AUTOSAR XML (schema 4.0)
package /Powertrain_Components
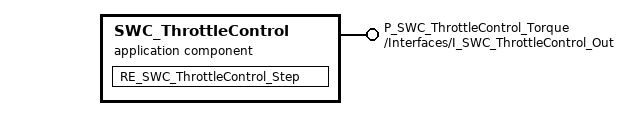
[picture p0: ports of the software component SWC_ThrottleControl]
  application sw component type SWC_ThrottleControl  # AUTOSAR Application SWC SWC_ThrottleControl for Powertrain Control
    provide port P_SWC_ThrottleControl_Torque: provided-interface=/Interfaces/I_SWC_ThrottleControl_Out
    behavior SWC_ThrottleControl_Behavior
      runnable RE_SWC_ThrottleControl_Step: symbol=SWC_ThrottleControl_Step
  sender receiver interface I_SWC_ThrottleControl_Out
    data DE_SWC_ThrottleControl_TorqueDemand: type=/AUTOSAR/Platform/uint32
